# AC78xx register map
Vendor: AutoChips; Series: AC78xx; File version: 1.0
CPU: CM3 r2p1, little endian, MPU, no FPU, 3 interrupt priority bits
Registers are 32-bit, read-write, no defined reset value unless marked. A register's access mark holds for its fields unless they carry their own. Offsets are from the block's base; [hi:lo] are bit positions; {n}, {i} and the like mark numbered series.

## CAN1
Base 0x400078A0; register names take the prefix CAN1_
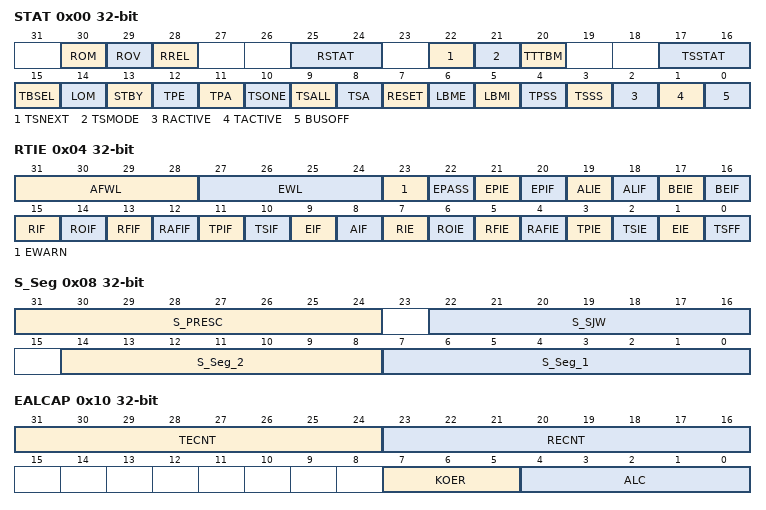
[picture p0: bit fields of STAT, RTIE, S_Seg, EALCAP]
0x00 STAT — configuration and status register
  [30] ROM — Receive Buffer Overflow Mode
  [29] ROV — Receive Buffer Overflow
  [28] RREL — Receive Buffer Release
  [25:24] RSTAT ro — Receive Buffer status bits
  [22] TSNEXT — Transmit Buffer Secondary next
  [21] TSMODE — Transmit buffer Secondary operation Mode
  [20] TTTBM — TTCAN Transmit Buffer Mode
  [17:16] TSSTAT — Transmit Secondary status bits
  [15] TBSEL — Transmit Buffer Select
  [14] LOM — Listen Only mode
  [13] STBY — Transceiver Standby mode
  [12] TPE — Transmit Primary Enable
  [11] TPA — Transmit Primary Abort
  [10] TSONE — Transmit Secondary one Frame
  [9] TSALL — Transmit Secondary All frames
  [8] TSA — Transmit Secondary Abort
  [7] RESET — reset request bit
  [6] LBME — Loop back mode, external
  [5] LBMI — Loop back mode internal
  [4] TPSS — Transmission Primary single shot mode for PTB
  [3] TSSS — Transmission Secondary single shot mode for STB
  [2] RACTIVE — Reception Active
  [1] TACTIVE — Transmission Active
  [0] BUSOFF — BUS off status
0x04 RTIE — Receive and Transmit Interrupt Enable Register
  [31:28] AFWL — Receive Buffer Almost Full Warning Limit
  [27:24] EWL — Programmable Error Warnig Limit
  [23] EWARN — Error Warning Limit Reached
  [22] EPASS — Error Passive Mode Active enable bit
  [21] EPIE — Error Passive Interrupt Enable
  [20] EPIF — Error Passive Interrupt Flag
  [19] ALIE — Arbitration Lost Interrupt Enable
  [18] ALIF — Arbitration Lost Interrupt Flag
  [17] BEIE — Bus Error Interrupt Enable
  [16] BEIF — Bus Error Interrupt flag
  [15] RIF — Receive Interrupt flag
  [14] ROIF — RB Overflow Interrupt flag
  [13] RFIF — RB Full Interrupt flag
  [12] RAFIF — RB Almost Full Interrupt flag
  [11] TPIF — Transmission Primary Interrupt Flag
  [10] TSIF — Transmission Secondary Interrupt Flag
  [9] EIF — Error Interrupt Flag
  [8] AIF — Abort Interrupt Flag
  [7] RIE — Receive Interrupt enable
  [6] ROIE — RB Overflow Interrupt enable
  [5] RFIE — RB Full Interrupt Enable
  [4] RAFIE — RB Almost Full Interrupt Enable
  [3] TPIE — Transmit Primary Interrupt Enable
  [2] TSIE — Transmit Secondary Interrupt Enable
  [1] EIE — Error Interrupt Enable
  [0] TSFF — Transmit Secondary Buffer full flag
0x08 S_Seg — Bit Timing Register
  [31:24] S_PRESC — Prescaler
  [22:16] S_SJW — Synchronization Jump Width
  [14:8] S_Seg_2 — Bit Timing Segment 2
  [7:0] S_Seg_1 — Bit Timing Segment 1
0x10 EALCAP — Error and Arbitration Lost Capture Register
  [31:24] TECNT ro — Transmit Error Count
  [23:16] RECNT ro — Receive Error Count
  [7:5] KOER ro — Kind of Error
  [4:0] ALC ro — Arbitration Lost Capture
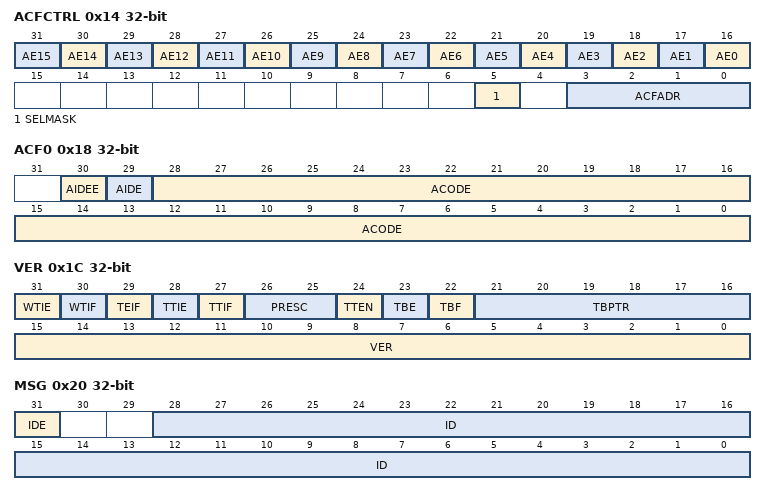
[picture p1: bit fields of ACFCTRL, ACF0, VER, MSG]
0x14 ACFCTRL — Acceptance Filter Control Register
  [n+16] AE{n} (n=0..15) — Acceptance Filter Enable
  [5] SELMASK — Select Acceptance MASK
  [3:0] ACFADR — Acceptance filter address
0x18 ACF0 — Acceptance Code Register
  [30] AIDEE — Acceptance Mask IDE bit check enable
  [29] AIDE — Acceptance Mask IDE Bit value
  [28:0] ACODE — Acceptance Code
0x1C VER — Version Information Register 0
  [31] WTIE — Watch Trigger Interrupt Enable
  [30] WTIF — Watch Trigger Interrupt Flag
  [29] TEIF — Trigger Error Interrupt Flag
  [28] TTIE — Timer Trigger Interrupt Enable
  [27] TTIF — Timer Trigger Interrupt Flag
  [26:25] PRESC — TTCAN Timer Prescaler
  [24] TTEN — Timer Trigger Enable
  [23] TBE — set TB slot to "Empty"
  [22] TBF — set TB slot to "Filled"
  [21:16] TBPTR — pointer to a TB message slot
  [15:0] VER — Version of CAN-CTRL
0x20 MSG — TTCAN: Reference Message
  [31] IDE — Reference Message IDE Bit
  [28:0] ID — Reference Message
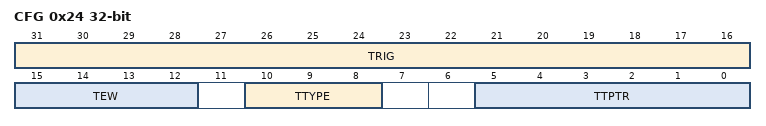
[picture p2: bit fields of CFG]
0x24 CFG — TTCAN:Trigger Configuration
  [31:16] TRIG — trigger time
  [15:12] TEW — Transmit enable window
  [10:8] TTYPE — trigger type
  [5:0] TTPTR — Transmit Trigger TB Slot Pointer
0x28 WTRIG — TTCAN: Watch Trigger Tim
  [15:0] WTRIG — watch trigger time

## CAN2
Base 0x40007CA0; register names take the prefix CAN2_
Registers as CAN1.
